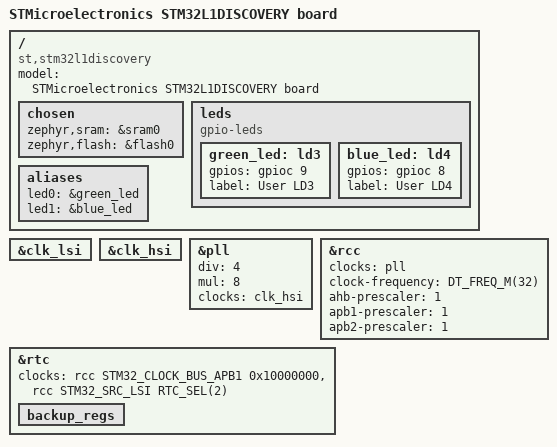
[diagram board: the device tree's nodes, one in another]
/*
 * Copyright (c) 2019 eTactica ehf
 *
 * SPDX-License-Identifier: Apache-2.0
 */

/dts-v1/;
#include <st/l1/stm32l100rc.dtsi>
#include <zephyr/dt-bindings/input/input-event-codes.h>

/ {
	model = "STMicroelectronics STM32L1DISCOVERY board";
	compatible = "st,stm32l1discovery";

	chosen {
		zephyr,sram = &sram0;
		zephyr,flash = &flash0;
	};

	leds {
		compatible = "gpio-leds";
		green_led: ld3 {
			gpios = <&gpioc 9 GPIO_ACTIVE_HIGH>;
			label = "User LD3";
		};
		blue_led: ld4 {
			gpios = <&gpioc 8 GPIO_ACTIVE_HIGH>;
			label = "User LD4";
		};
	};

	aliases {
		led0 = &green_led;
		led1 = &blue_led;
	};
};

&clk_lsi {
	status = "okay";
};

&clk_hsi {
	status = "okay";
};

&pll {
	div = <4>;
	mul = <8>;
	/* out of the box, MCO from stlink is not enabled, unlike later discos */
	clocks = <&clk_hsi>;
	status = "okay";
};

&rcc {
	clocks = <&pll>;
	clock-frequency = <DT_FREQ_M(32)>;
	ahb-prescaler = <1>;
	apb1-prescaler = <1>;
	apb2-prescaler = <1>;
};

&rtc {
	clocks = <&rcc STM32_CLOCK_BUS_APB1 0x10000000>,
		 <&rcc STM32_SRC_LSI RTC_SEL(2)>;
	status = "okay";

	backup_regs {
		status = "okay";
	};
};
